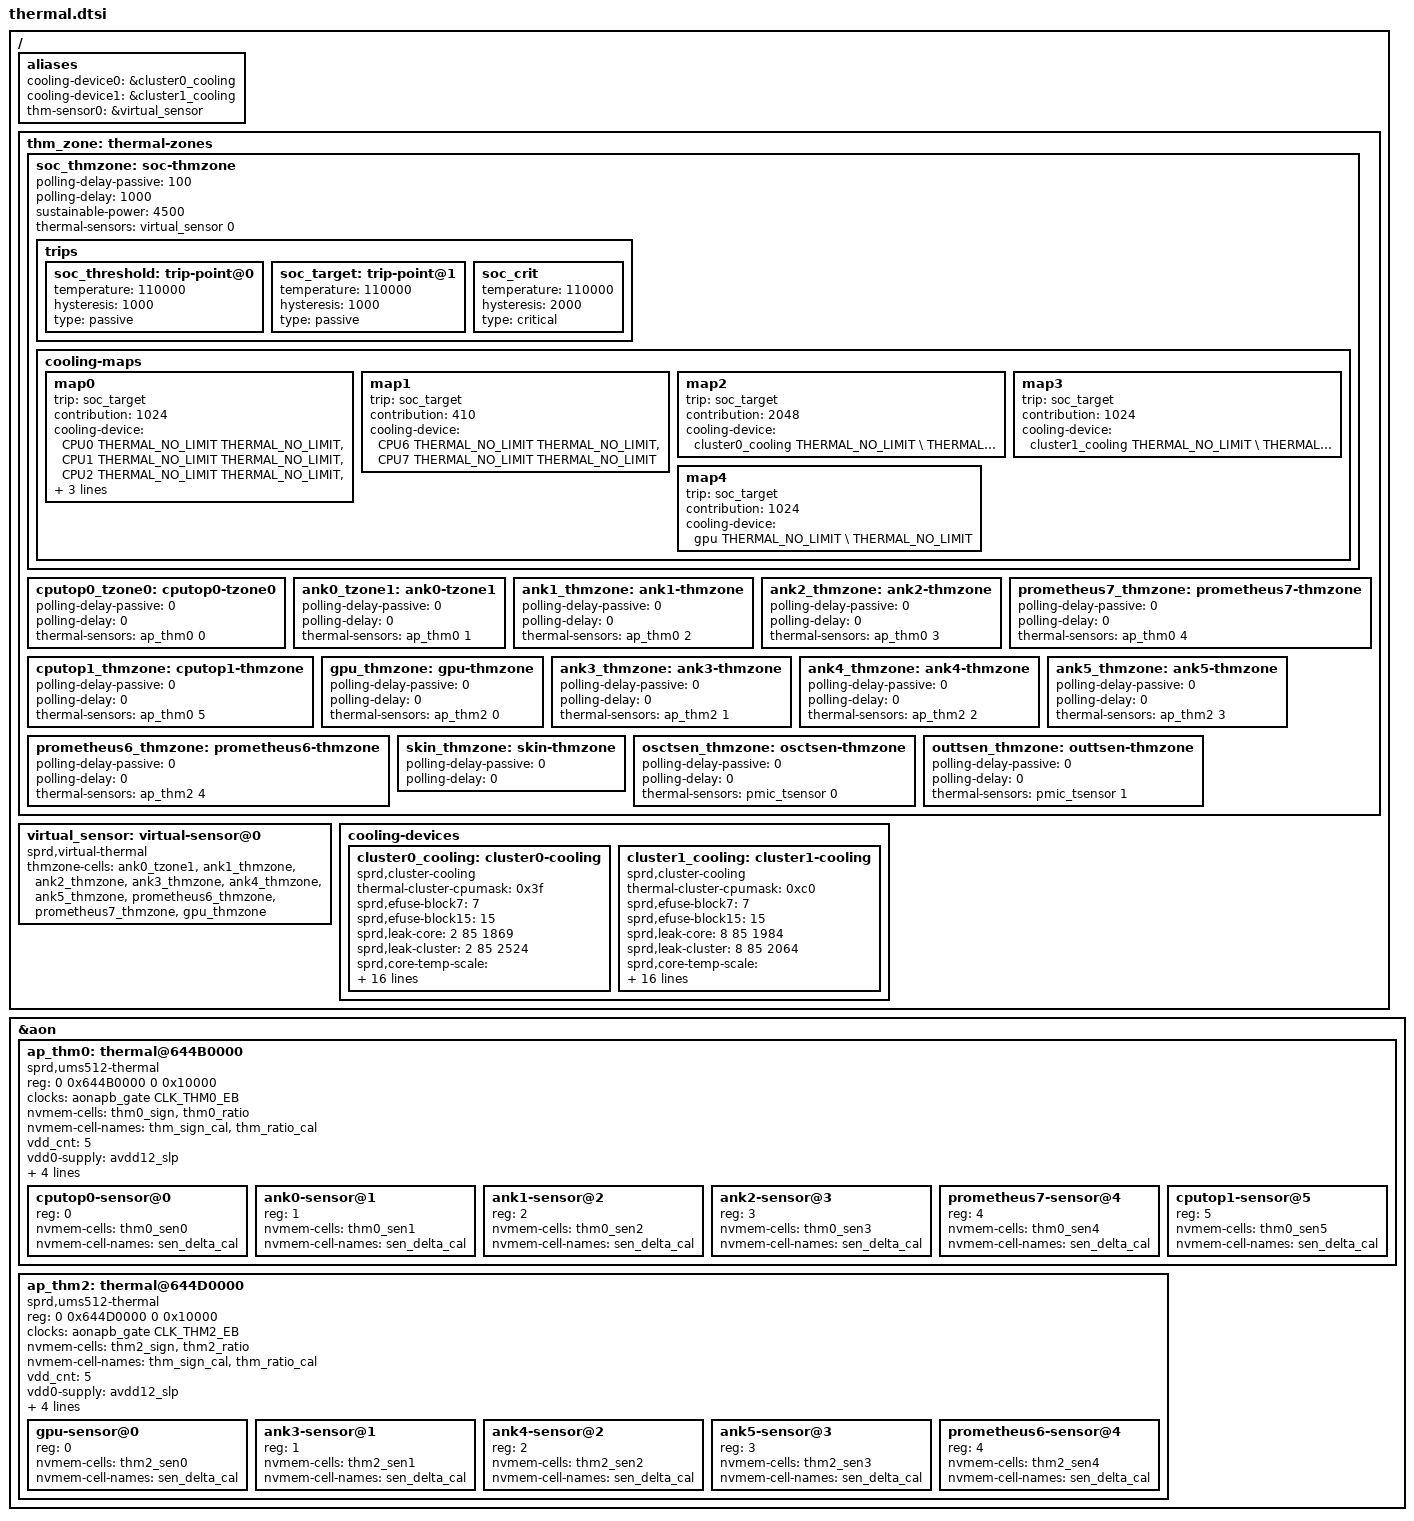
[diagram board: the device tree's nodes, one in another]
// SPDX-License-Identifier: (GPL-2.0+ OR MIT)
/*
 * Copyright (C) 2020, Unisoc Inc.
 */

#include <dt-bindings/thermal/thermal.h>

&aon {
	ap_thm0: thermal@644B0000 {
		compatible = "sprd,ums512-thermal", "sprd,qogirl6-thermal";
		reg = <0 0x644B0000 0 0x10000>;
		clock-names = "enable";
		clocks = <&aonapb_gate CLK_THM0_EB>;
		#thermal-sensor-cells = <1>;
		nvmem-cells = <&thm0_sign>, <&thm0_ratio>;
		nvmem-cell-names = "thm_sign_cal", "thm_ratio_cal";
		#address-cells = <1>;
		#size-cells = <0>;
		vdd_cnt = <5>;
		vdd0-supply = <&avdd12_slp>;
		vdd1-supply = <&avdd18_slp>;
		vdd2-supply = <&vddmodem_slp>;
		vdd3-supply = <&vddgen1_slp>;
		vdd4-supply = <&vddgpu_slp>;
		cputop0-sensor@0 {
			reg = <0>;
			nvmem-cells = <&thm0_sen0>;
			nvmem-cell-names = "sen_delta_cal";
		};

		ank0-sensor@1 {
			reg = <1>;
			nvmem-cells = <&thm0_sen1>;
			nvmem-cell-names = "sen_delta_cal";
		};

		ank1-sensor@2 {
			reg = <2>;
			nvmem-cells = <&thm0_sen2>;
			nvmem-cell-names = "sen_delta_cal";
		};

		ank2-sensor@3 {
			reg = <3>;
			nvmem-cells = <&thm0_sen3>;
			nvmem-cell-names = "sen_delta_cal";
		};

		prometheus7-sensor@4 {
			reg = <4>;
			nvmem-cells = <&thm0_sen4>;
			nvmem-cell-names = "sen_delta_cal";
		};

		cputop1-sensor@5 {
			reg = <5>;
			nvmem-cells = <&thm0_sen5>;
			nvmem-cell-names = "sen_delta_cal";
		};
	};

	ap_thm2: thermal@644D0000 {
		compatible = "sprd,ums512-thermal", "sprd,qogirl6-thermal";
		reg = <0 0x644D0000 0 0x10000>;
		clock-names = "enable";
		clocks = <&aonapb_gate CLK_THM2_EB>;
		#thermal-sensor-cells = <1>;
		nvmem-cells = <&thm2_sign>, <&thm2_ratio>;
		nvmem-cell-names = "thm_sign_cal", "thm_ratio_cal";
		#address-cells = <1>;
		#size-cells = <0>;
		vdd_cnt = <5>;
		vdd0-supply = <&avdd12_slp>;
		vdd1-supply = <&avdd18_slp>;
		vdd2-supply = <&vddmodem_slp>;
		vdd3-supply = <&vddgen1_slp>;
		vdd4-supply = <&vddgpu_slp>;

		gpu-sensor@0 {
			reg = <0>;
			nvmem-cells = <&thm2_sen0>;
			nvmem-cell-names = "sen_delta_cal";
		};

		ank3-sensor@1 {
			reg = <1>;
			nvmem-cells = <&thm2_sen1>;
			nvmem-cell-names = "sen_delta_cal";
		};

		ank4-sensor@2 {
			reg = <2>;
			nvmem-cells = <&thm2_sen2>;
			nvmem-cell-names = "sen_delta_cal";
		};

		ank5-sensor@3 {
			reg = <3>;
			nvmem-cells = <&thm2_sen3>;
			nvmem-cell-names = "sen_delta_cal";
		};

		prometheus6-sensor@4 {
			reg = <4>;
			nvmem-cells = <&thm2_sen4>;
			nvmem-cell-names = "sen_delta_cal";
		};
	};
};

/{
	aliases {
		cooling-device0 = &cluster0_cooling;
		cooling-device1 = &cluster1_cooling;
		thm-sensor0 = &virtual_sensor;
	};

	thm_zone: thermal-zones {
		soc_thmzone: soc-thmzone {
			polling-delay-passive = <100>;
			polling-delay = <1000>;
			sustainable-power = <4500>;
			thermal-sensors = <&virtual_sensor  0>;
			trips {
				soc_threshold: trip-point@0 {
					temperature = <110000>;
					hysteresis = <1000>;
					type = "passive";
				};
				soc_target: trip-point@1 {
					temperature = <110000>;
					hysteresis = <1000>;
					type = "passive";
				};
				soc_crit: soc_crit {
					temperature = <110000>;
					hysteresis = <2000>;
					type = "critical";
				};
			};
			cooling-maps {
				map0 {
					trip = <&soc_target>;
					contribution = <1024>;
					cooling-device =
					<&CPU0 THERMAL_NO_LIMIT THERMAL_NO_LIMIT>,
					<&CPU1 THERMAL_NO_LIMIT THERMAL_NO_LIMIT>,
					<&CPU2 THERMAL_NO_LIMIT THERMAL_NO_LIMIT>,
					<&CPU3 THERMAL_NO_LIMIT THERMAL_NO_LIMIT>,
					<&CPU4 THERMAL_NO_LIMIT THERMAL_NO_LIMIT>,
					<&CPU5 THERMAL_NO_LIMIT THERMAL_NO_LIMIT>;
				};
				map1 {
					trip = <&soc_target>;
					contribution = <410>;
					cooling-device =
					<&CPU6 THERMAL_NO_LIMIT THERMAL_NO_LIMIT>,
					<&CPU7 THERMAL_NO_LIMIT THERMAL_NO_LIMIT>;
				};
				map2 {
					trip = <&soc_target>;
					contribution = <2048>;
					cooling-device =
					<&cluster0_cooling THERMAL_NO_LIMIT \
					THERMAL_NO_LIMIT>;
				};
				map3 {
					trip = <&soc_target>;
					contribution = <1024>;
					cooling-device =
					<&cluster1_cooling THERMAL_NO_LIMIT \
					THERMAL_NO_LIMIT>;
				};
				map4 {
					trip = <&soc_target>;
					contribution = <1024>;
					cooling-device =
					<&gpu THERMAL_NO_LIMIT \
					THERMAL_NO_LIMIT>;
				};
			};
		};

		cputop0_tzone0: cputop0-tzone0 {
			polling-delay-passive = <0>;
			polling-delay = <0>;
			thermal-sensors = <&ap_thm0 0>;
		};

		ank0_tzone1: ank0-tzone1 {
			polling-delay-passive = <0>;
			polling-delay = <0>;
			thermal-sensors = <&ap_thm0 1>;
		};

		ank1_thmzone: ank1-thmzone {
			polling-delay-passive = <0>;
			polling-delay = <0>;
			thermal-sensors = <&ap_thm0 2>;
		};

		ank2_thmzone: ank2-thmzone {
			polling-delay-passive = <0>;
			polling-delay = <0>;
			thermal-sensors = <&ap_thm0 3>;
		};

		prometheus7_thmzone: prometheus7-thmzone {
			polling-delay-passive = <0>;
			polling-delay = <0>;
			thermal-sensors = <&ap_thm0 4>;
		};

		cputop1_thmzone: cputop1-thmzone {
			polling-delay-passive = <0>;
			polling-delay = <0>;
			thermal-sensors = <&ap_thm0 5>;
		};

		gpu_thmzone: gpu-thmzone {
			polling-delay-passive = <0>;
			polling-delay = <0>;
			thermal-sensors = <&ap_thm2 0>;
		};

		ank3_thmzone: ank3-thmzone {
			polling-delay-passive = <0>;
			polling-delay = <0>;
			thermal-sensors = <&ap_thm2 1>;
		};

		ank4_thmzone: ank4-thmzone {
			polling-delay-passive = <0>;
			polling-delay = <0>;
			thermal-sensors = <&ap_thm2 2>;
		};

		ank5_thmzone: ank5-thmzone {
			polling-delay-passive = <0>;
			polling-delay = <0>;
			thermal-sensors = <&ap_thm2 3>;
		};

		prometheus6_thmzone: prometheus6-thmzone {
			polling-delay-passive = <0>;
			polling-delay = <0>;
			thermal-sensors = <&ap_thm2 4>;
		};

		skin_thmzone: skin-thmzone {
			polling-delay-passive = <0>;
			polling-delay = <0>;
		};

		osctsen_thmzone: osctsen-thmzone {
			 polling-delay-passive = <0>;
			 polling-delay = <0>;
			 thermal-sensors = <&pmic_tsensor 0>;
		 };

		outtsen_thmzone: outtsen-thmzone {
			 polling-delay-passive = <0>;
			 polling-delay = <0>;
			 thermal-sensors = <&pmic_tsensor 1>;
		 };
	};

	virtual_sensor: virtual-sensor@0 {
		compatible = "sprd,virtual-thermal";
		#thermal-sensor-cells = <1>;
		thmzone-cells = <&ank0_tzone1>, <&ank1_thmzone>,
			<&ank2_thmzone>, <&ank3_thmzone>, <&ank4_thmzone>,
			<&ank5_thmzone>, <&prometheus6_thmzone>,
			<&prometheus7_thmzone>, <&gpu_thmzone>;
	};

	cooling-devices {
		cluster0_cooling: cluster0-cooling {
			compatible = "sprd,cluster-cooling";
			#cooling-cells = <2>; /* min followed by max */
			thermal-cluster-cpumask = <0x3f>;
			sprd,efuse-block7 = <7>;
			sprd,efuse-block15 = <15>;
			/* core_leak =                             */
			/*(LIT_LEAK[4:0]+1) x 2mA x 0.85V x 18.69% */
			sprd,leak-core = <2 85 1869>;
			/* cluster_leak =                           */
			/* (LIT_LEAK[4:0]+1) x 2mA x 0.85V x 25.24% */
			sprd,leak-cluster = <2 85 2524>;
			/*core Tscale = aT^3 + bT^2 + cT +di   */
			sprd,core-temp-scale =
			/* a*10^7   b*10^7      c*10^7     d*10^7 */
			<  15      (-730)      70000    (-120000)>;
			/*core Vscale = eV^3 + fV^2 + gV + h */
			sprd,core-voltage-scale =
			/* e*10^2   f*10^2     g*10^2  h*10^2*/
			<  792     (-1868)      1581      (-406)>;
			/*cluster Tscale = aT^3 + bT^2 + cT +di   */
			sprd,cluster-temp-scale =
			/* a*10^7   b*10^7      c*10^7     d*10^7 */
			<  15      (-728)      70000    (-120000)>;
			/*cluster Vscale = eV^3 + fV^2 + gV + h */
			sprd,cluster-voltage-scale =
			/* e*10^2   f*10^2     g*10^2  h*10^2*/
			<  792     (-1868)      1582      (-406)>;
			sprd,efuse-switch = <0>;
			sprd,hotplug-period = <10>;
			sprd,min-cpufreq = <614400>;
			sprd,min-cpunum = <6>;
			sprd,max-temp = <90000>;
			sprd,core-base = <4075>;
			sprd,cluster-base = <3891>;
			sprd,dynamic-core =
			/*Pdynperghz*10    Freq     Vbase  */
			< 889           1000     1000>;
			sprd,dynamic-cluster =
			/*Pdynperghz*10    Freq     Vbase  */
			< 322           1000     1000>;
		};

		cluster1_cooling: cluster1-cooling {
			compatible = "sprd,cluster-cooling";
			#cooling-cells = <2>; /* min followed by max */
			thermal-cluster-cpumask = <0xc0>;
			sprd,efuse-block7 = <7>;
			sprd,efuse-block15 = <15>;
			/* core_leak =                             */
			/*(LIT_LEAK[4:0]+1) x 2mA x 0.85V x 18.69% */
			sprd,leak-core = <8 85 1984>;
			/* cluster_leak =                           */
			/* (LIT_LEAK[4:0]+1) x 2mA x 0.85V x 25.24% */
			sprd,leak-cluster = <8 85 2064>;
			/*core Tscale = aT^3 + bT^2 + cT +d  */
			sprd,core-temp-scale =
			/* a*10^7   b*10^7	c*10^7	   d*10^7*/
			<  15      (-728)      70000    (-120000)>;
			/* core  Vscale = eV^3 + fV^2 + gV + h */
			sprd,core-voltage-scale =
			/* e*10^2  f*10^2     g*10^2  h*10^2*/
			<  792     (-1868)      1582      (-406)>;
			/*cluster Tscale = aT^3 + bT^2 + cT +di   */
			sprd,cluster-temp-scale =
			/* a*10^7   b*10^7      c*10^7     d*10^7 */
			<  15      (-728)      70000    (-120000)>;
			/*cluster Vscale = eV^3 + fV^2 + gV + h */
			sprd,cluster-voltage-scale =
			/* e*10^2   f*10^2     g*10^2  h*10^2*/
			<  792     (-1868)      1582      (-406)>;
			sprd,efuse-switch = <0>;
			sprd,hotplug-period = <10>;
			sprd,min-cpufreq = <1228800>;
			sprd,min-cpunum = <0>;
			sprd,max-temp = <85000>;
			sprd,core-base = <11051>;
			sprd,cluster-base = <3891>;
			sprd,dynamic-core =
			/* Pdynperghz*10    Freq     Vbase */
			<  4209          1000     1000>;
			sprd,dynamic-cluster =
			/* Pdynperghz*10    Freq     Vbase */
			<  322           1000     1000>;
		};
	};
};
